# DP32G030 register map
File version: 1.0
CPU: CM0 r0p0, little endian, no MPU, no FPU, 4 interrupt priority bits
Registers are 32-bit, read-write, reset 0x0 unless marked. A register's access mark holds for its fields unless they carry their own. Offsets are from the block's base; [hi:lo] are bit positions.

## FLASH_CTRL — FLASH_CTRL unit
Base 0x4006F000
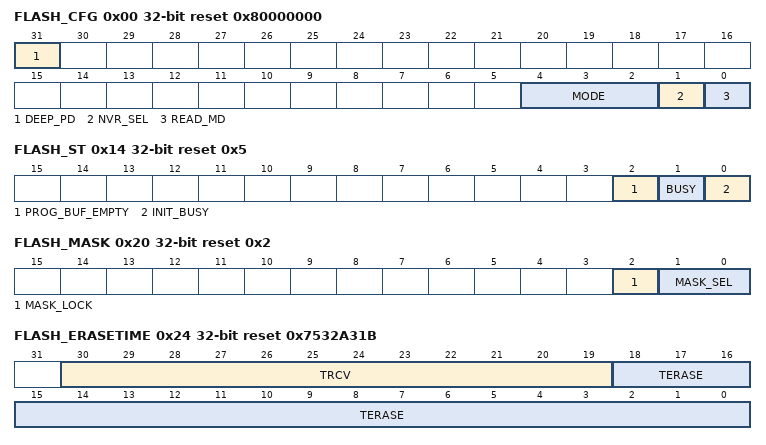
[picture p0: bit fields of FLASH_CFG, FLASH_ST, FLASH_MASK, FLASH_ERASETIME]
0x00 FLASH_CFG reset 0x80000000 — Flash configuration register
  [31] DEEP_PD — Configure FLASH to enter low-power mode Note: This operation can only be performed in RAM. Values: 1: Enter low power mode 0: Normal operating mode
  [4:2] MODE — Operating Mode Configuration Register Note 1: All the above operations can only be performed in RAM. Note 2: MODE must be configured back to 0 every time other operation modes (other than normal read operation mode) are completed. Values: 000: Normal read operation. Used for AHB read operation mode. 001: Programming operation. Program the data to be programmed into the address starting from the address in FLASH_ADDR. The maximum number of sectors to be programmed is half a sector (256 bytes) at a time, and only half a sector can be programmed. 010: Sector erase operation (512 bytes per sector). The address of the corresponding erased sector is specified by FLASH_ADDR.
  [1] NVR_SEL — NVR Zone Selection Note: This register change must be performed in RAM. Values: 0: Main Array selected (128 sectors, 512 bytes per sector) 1: Selects the NVR sector (4 sectors, 512 bytes each)
  [0] READ_MD — Read Rate Mode Selection Note: This register change must be performed in RAM. Values: 1: 2 system clock cycles wait (56MHz<sys_clk<84MHz) 0: 1 system clock cycle wait (sys_clk<=56MHz)
0x04 FLASH_ADDR — Flash Address Configuration Register
  [13:0] ADDR — Address register for program/sector erase operations The starting address, in words, at which the programming operation is initiated. The maximum programming data for each consecutive programming is half a sector, i.e., the maximum programming data is 64 words, and programming can only be performed in half a sector; When the sector erase operation is started, bit7-bit13 indicates the sector number to be erased; that is, 1 sector 512Byte.
0x08 FLASH_WDATA access not given — Flash write data register
0x0C FLASH_RDATA access not given — Flash read data register
0x10 FLASH_START — Flash Operation Start Register
  [0] START — Operational startup control bits Writing this bit to 1 initiates the command operation configured in the MODE register. This bit is automatically cleared when the current command operation is completed
0x14 FLASH_ST ro reset 0x5 — Flash status register
  [2] PROG_BUF_EMPTY — Programming Data Cache Register Empty Status Flag 1: Indicates that the Programming Data Cache Register is empty. The next word of data can be written. 0: Indicates that the Programming Data Cache Register is non-empty and the next word of data cannot be written. Writing the next word data during the current word programming is programmed consecutively, otherwise Terminates continuous programming operation.
  [1] BUSY — Controller Busy Flag 1: Indicates that the controller is in the process of the current command operation. 0: Indicates that the controller is in the READY state, waiting for the command operation to be executed.
  [0] INIT_BUSY — FLASH Initialization Busy Flag 1: Indicates that flash initialization is in progress. 0: Indicates initialization is complete.
0x18 FLASH_LOCK wo — Flash Operation Lock Control Register
  [7:0] LOCK — Operator lock control Writing 0x55 to this register locks the operation start and START cannot be written 1. Used to protect against misoperation of FLASH. Power-up is locked by default.
0x1C FLASH_UNLOCK wo — Flash Operation Unlock Control Register
  [7:0] UNLOCK — Operation Unlock Controls Writing 0xAA to this register unlocks operation start and START can be written 1.
0x20 FLASH_MASK reset 0x2 — Flash mask control register
  [2] MASK_LOCK — MASK Select Lock Control When this bit is configured as 1, MASK_SEL cannot be changed. When this bit is set to 0, MASK_SEL can be modified.
  [1:0] MASK_SEL — MASK Selection 00: Unshielded 01: Minimum 2KB (i.e., minimum 4 sectors) blocked 10: Minimum 4KB (i.e., minimum 8 sectors) blocked 11: Minimum 8KB (i.e., minimum 16 sectors) blocked
0x24 FLASH_ERASETIME reset 0x7532A31B — Flash Erase Time Parameter Configuration Register
  [30:19] TRCV — FLASH Sector Erase Time, TRCV Time Register Depending on the frequency of the system clock, the TRCV needs to be configured appropriately so that its timing is at least greater than the 50us requirement. Sector erase operation can be operated with a system clock of up to 72MHz. Note 1: The default value is the configured value for the sector erase operation when the system clock is 48MHz.
  [18:0] TERASE — FLASH Sector Erase Time, TERASE Time Register Depending on the frequency of the system clock, the TERASE needs to be configured appropriately so that the TERASE time is in the range of 3.2ms-4ms. The sector erase operation works with a system clock of up to 72MHz; Note 1: The default value is the configured value for the sector erase operation when the system clock is 48MHz.
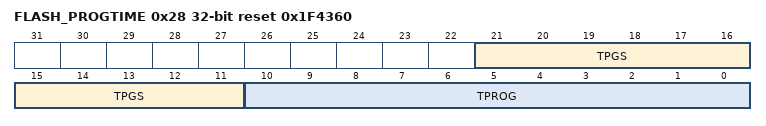
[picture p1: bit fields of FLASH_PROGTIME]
0x28 FLASH_PROGTIME reset 0x1F4360 — Flash Program Time Parameter Configuration Register
  [21:11] TPGS — TPGS Time Control Register for FLASH programming operations. Depending on the frequency of the system clock, the TPGS needs to be configured appropriately so that its timing is at least greater than the 20us requirement. Note: Default value is for system clock at 48MHz.
  [10:0] TPROG — TPROG time control register for FLASH programming operation. The TPROG time needs to be in the range of 16us-20us when programming; Depending on the frequency of the system clock, the TPROG needs to be configured appropriately so that it is within the proper range. Note: Default value is for system clock at 48MHz.
